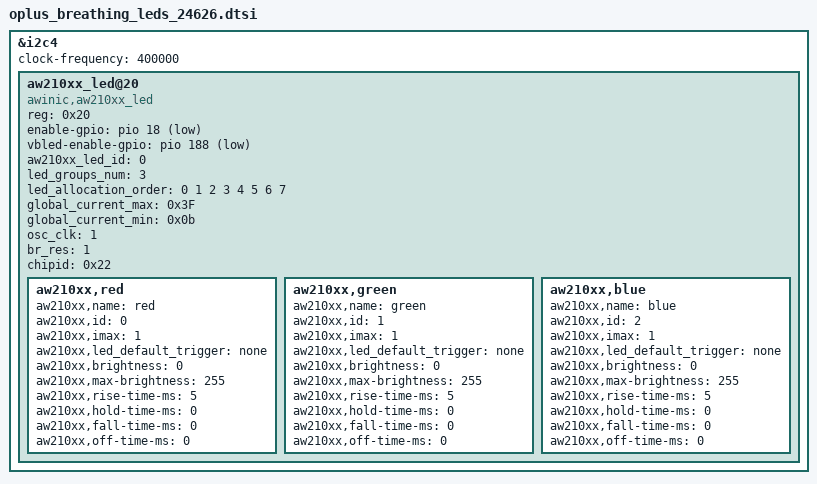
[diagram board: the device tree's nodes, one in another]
&i2c4 {
	status = "ok";
	clock-frequency = <400000>;

	aw210xx_led@20 {
		compatible = "awinic,aw210xx_led";
		reg = <0x20>;

		/* Power Config */
		enable-gpio = <&pio 18 0x1>;
		vbled-enable-gpio = <&pio 188 0x1>;

		aw210xx_led_id = <0>;
		led_groups_num = <3>;
		/* led_allocation_order = <1 3 5 7 2 4 6 8>; */
		led_allocation_order = <0 1 2 3 4 5 6 7>; /* this means place 1st rgb into index 1, 2nd into index 5 and so on*/
		global_current_max = <0x3F>; /*gcc value of current*/
		global_current_min = <0x0b>;
		osc_clk = <1>;
		br_res = <1>;
		chipid = <0x22>;
		status = "okay";

		aw210xx,red {
			aw210xx,name = "red";
			aw210xx,id = <0>;
			aw210xx,imax = <1>;
			aw210xx,led_default_trigger = "none";
			aw210xx,brightness = <0>;
			aw210xx,max-brightness = <255>;
			aw210xx,rise-time-ms = <5>;
			aw210xx,hold-time-ms = <0>;
			aw210xx,fall-time-ms = <0>;
			aw210xx,off-time-ms = <0>;
		};
		aw210xx,green {
			aw210xx,name = "green";
			aw210xx,id = <1>;
			aw210xx,imax = <1>;
			aw210xx,led_default_trigger = "none";
			aw210xx,brightness = <0>;
			aw210xx,max-brightness = <255>;
			aw210xx,rise-time-ms = <5>;
			aw210xx,hold-time-ms = <0>;
			aw210xx,fall-time-ms = <0>;
			aw210xx,off-time-ms = <0>;
		};
		aw210xx,blue {
			aw210xx,name = "blue";
			aw210xx,id = <2>;
			aw210xx,imax = <1>;
			aw210xx,led_default_trigger = "none";
			aw210xx,brightness = <0>;
			aw210xx,max-brightness = <255>;
			aw210xx,rise-time-ms = <5>;
			aw210xx,hold-time-ms = <0>;
			aw210xx,fall-time-ms = <0>;
			aw210xx,off-time-ms = <0>;
		};
	};
};

